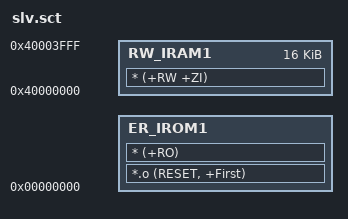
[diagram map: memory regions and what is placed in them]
; *************************************************************
; *** Scatter-Loading Description File generated by uVision ***
; *************************************************************

LR_IROM1 0x00000000 0x00040000  {  ; load region
  ER_IROM1 0x00000000  {       ; load address = execution address
   *.o (RESET, +First)
   * (+RO)
  }
  RW_IRAM1 0x40000000 0x00004000  {  ; RW data
   * (+RW +ZI)
  }
}

